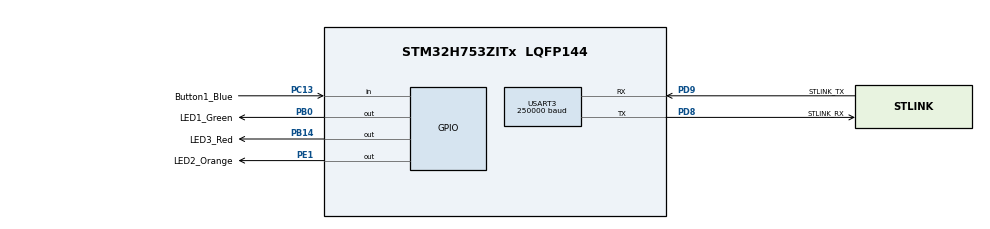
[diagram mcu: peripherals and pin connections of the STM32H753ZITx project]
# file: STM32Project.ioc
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CORTEX_M7.CPU_DCache=Disabled
CORTEX_M7.CPU_ICache=Disabled
CORTEX_M7.MPU_Control=__NULL
CORTEX_M7.default_mode_Activation=1
Mcu.Family=STM32H7
Mcu.Name=STM32H753ZITx
Mcu.Package=LQFP144
NVIC.PriorityGroup=NVIC_PRIORITYGROUP_4
NVIC.TIM7_IRQn=true\:15\:0\:false\:false\:true\:false\:true\:true
NVIC.TimeBase=TIM7_IRQn
NVIC.TimeBaseIP=TIM7
PA13\ (JTMS/SWDIO).Mode=Trace_Asynchronous_SW
PA13\ (JTMS/SWDIO).Signal=DEBUG_JTMS-SWDIO
PA14\ (JTCK/SWCLK).Mode=Trace_Asynchronous_SW
PA14\ (JTCK/SWCLK).Signal=DEBUG_JTCK-SWCLK
PB0.GPIO_Label=LED1_Green
PB0.Signal=GPIO_Output
PB14.GPIO_Label=LED3_Red
PB14.Signal=GPIO_Output
PB3\ (JTDO/TRACESWO).Mode=Trace_Asynchronous_SW
PB3\ (JTDO/TRACESWO).Signal=DEBUG_JTDO-SWO
PC13.GPIO_Label=Button1_Blue
PC13.Signal=GPIO_Input
PC14-OSC32_IN\ (OSC32_IN).Mode=LSE-External-Oscillator
PC14-OSC32_IN\ (OSC32_IN).Signal=RCC_OSC32_IN
PC15-OSC32_OUT\ (OSC32_OUT).Mode=LSE-External-Oscillator
PC15-OSC32_OUT\ (OSC32_OUT).Signal=RCC_OSC32_OUT
PD8.GPIO_Label=STLINK_RX
PD8.GPIO_Speed=GPIO_SPEED_FREQ_VERY_HIGH
PD8.Mode=Asynchronous
PD8.Signal=USART3_TX
PD9.GPIO_Label=STLINK_TX
PD9.GPIO_Speed=GPIO_SPEED_FREQ_VERY_HIGH
PD9.Mode=Asynchronous
PD9.Signal=USART3_RX
PE1.GPIO_Label=LED2_Orange
PE1.Signal=GPIO_Output
PH0-OSC_IN\ (PH0).Mode=HSE-External-Clock-Source
PH0-OSC_IN\ (PH0).Signal=RCC_OSC_IN
PH1-OSC_OUT\ (PH1).Signal=RCC_OSC_OUT
ProjectManager.HeapSize=0x400
ProjectManager.StackSize=0x1000
ProjectManager.TargetToolchain=CMake
RCC.ADCFreq_Value=50000000
RCC.APB1Freq_Value=120000000
RCC.APB2Freq_Value=120000000
RCC.APB3Freq_Value=120000000
RCC.APB4Freq_Value=120000000
RCC.CortexFreq_Value=480000000
RCC.D1PPRE=RCC_APB3_DIV2
RCC.D2PPRE1=RCC_APB1_DIV2
RCC.D2PPRE2=RCC_APB2_DIV2
RCC.D3PPRE=RCC_APB4_DIV2
RCC.DIVM1=1
RCC.DIVM2=1
RCC.DIVM3=1
RCC.DIVN1=192
RCC.DIVN2=20
RCC.DIVN3=184
RCC.DIVQ1=4
RCC.HCLKFreq_Value=240000000
RCC.HPRE=RCC_HCLK_DIV2
RCC.HSE_VALUE=5000000
RCC.PLLFRACN=0
RCC.PLLSourceVirtual=RCC_PLLSOURCE_HSE
RCC.PWR_Regulator_Voltage_Scale=PWR_REGULATOR_VOLTAGE_SCALE0
RCC.RTCClockSelection=RCC_RTCCLKSOURCE_LSE
RCC.SYSCLKFreq_VALUE=480000000
RCC.SYSCLKSource=RCC_SYSCLKSOURCE_PLLCLK
RCC.USBFreq_Value=240000000
RTC.WeekDay=RTC_WEEKDAY_THURSDAY
RTC.Year=26
USART3.BaudRate=250000
USART3.VirtualMode-Asynchronous=VM_ASYNC
VP_MEMORYMAP_VS_MEMORYMAP.Mode=CurAppReg
VP_RTC_VS_RTC_Activate.Mode=RTC_Enabled
VP_RTC_VS_RTC_Calendar.Mode=RTC_Calendar
VP_SYS_VS_tim7.Mode=TIM7
board=NUCLEO-H753ZI

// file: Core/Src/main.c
/* USER CODE BEGIN Header */
/**
  ******************************************************************************
  * @file           : main.c
  * @brief          : Main program body
  ******************************************************************************
  * @attention
  *
  * Copyright (c) 2026 STMicroelectronics.
  * All rights reserved.
  *
  * This software is licensed under terms that can be found in the LICENSE file
  * in the root directory of this software component.
  * If no LICENSE file comes with this software, it is provided AS-IS.
  *
  ******************************************************************************
  */
/* USER CODE END Header */
#include "main.h"
#include "rtc.h"
#include "usart.h"
#include "gpio.h"

void SystemClock_Config(void);
/* USER CODE BEGIN PFP */
extern void Setup(void);
extern void Loop(void);
/* USER CODE END PFP */

int main(void)
{

  /* MCU Configuration--------------------------------------------------------*/

  /* Reset of all peripherals, Initializes the Flash interface and the Systick. */
  HAL_Init();

  /* Configure the system clock */
  SystemClock_Config();

  /* Initialize all configured peripherals */
  MX_GPIO_Init();
  MX_USART3_UART_Init();
  MX_RTC_Init();

  /* Infinite loop */
  /* USER CODE BEGIN WHILE */
  Setup(); // Call the C++ application main function in ./Application/application.cpp.

  while (1)
  {
    Loop(); // Cyclic call the C++ application loop function in ./Application/application.cpp.
    /* USER CODE END WHILE */

  }
}

void SystemClock_Config(void)
{
  RCC_OscInitTypeDef RCC_OscInitStruct = {0};
  RCC_ClkInitTypeDef RCC_ClkInitStruct = {0};

  /** Supply configuration update enable
  */
  HAL_PWREx_ConfigSupply(PWR_LDO_SUPPLY);

  /** Configure the main internal regulator output voltage
  */
  __HAL_PWR_VOLTAGESCALING_CONFIG(PWR_REGULATOR_VOLTAGE_SCALE0);

  while(!__HAL_PWR_GET_FLAG(PWR_FLAG_VOSRDY)) {}

  /** Configure LSE Drive Capability
  */
  HAL_PWR_EnableBkUpAccess();
  __HAL_RCC_LSEDRIVE_CONFIG(RCC_LSEDRIVE_LOW);

  /** Initializes the RCC Oscillators according to the specified parameters
  * in the RCC_OscInitTypeDef structure.
  */
  RCC_OscInitStruct.OscillatorType = RCC_OSCILLATORTYPE_HSE|RCC_OSCILLATORTYPE_LSE;
  RCC_OscInitStruct.HSEState = RCC_HSE_BYPASS;
  RCC_OscInitStruct.LSEState = RCC_LSE_ON;
  RCC_OscInitStruct.PLL.PLLState = RCC_PLL_ON;
  RCC_OscInitStruct.PLL.PLLSource = RCC_PLLSOURCE_HSE;
  RCC_OscInitStruct.PLL.PLLM = 1;
  RCC_OscInitStruct.PLL.PLLN = 192;
  RCC_OscInitStruct.PLL.PLLP = 2;
  RCC_OscInitStruct.PLL.PLLQ = 4;
  RCC_OscInitStruct.PLL.PLLR = 2;
  RCC_OscInitStruct.PLL.PLLRGE = RCC_PLL1VCIRANGE_2;
  RCC_OscInitStruct.PLL.PLLVCOSEL = RCC_PLL1VCOWIDE;
  RCC_OscInitStruct.PLL.PLLFRACN = 0;
  if (HAL_RCC_OscConfig(&RCC_OscInitStruct) != HAL_OK)
  {
    Error_Handler();
  }

  /** Initializes the CPU, AHB and APB buses clocks
  */
  RCC_ClkInitStruct.ClockType = RCC_CLOCKTYPE_HCLK|RCC_CLOCKTYPE_SYSCLK
                              |RCC_CLOCKTYPE_PCLK1|RCC_CLOCKTYPE_PCLK2
                              |RCC_CLOCKTYPE_D3PCLK1|RCC_CLOCKTYPE_D1PCLK1;
  RCC_ClkInitStruct.SYSCLKSource = RCC_SYSCLKSOURCE_PLLCLK;
  RCC_ClkInitStruct.SYSCLKDivider = RCC_SYSCLK_DIV1;
  RCC_ClkInitStruct.AHBCLKDivider = RCC_HCLK_DIV2;
  RCC_ClkInitStruct.APB3CLKDivider = RCC_APB3_DIV2;
  RCC_ClkInitStruct.APB1CLKDivider = RCC_APB1_DIV2;
  RCC_ClkInitStruct.APB2CLKDivider = RCC_APB2_DIV2;
  RCC_ClkInitStruct.APB4CLKDivider = RCC_APB4_DIV2;

  if (HAL_RCC_ClockConfig(&RCC_ClkInitStruct, FLASH_LATENCY_4) != HAL_OK)
  {
    Error_Handler();
  }
}

void HAL_TIM_PeriodElapsedCallback(TIM_HandleTypeDef *htim)
{
  if (htim->Instance == TIM7)
  {
    HAL_IncTick();
  }
}

void Error_Handler(void)
{
  __disable_irq();
  while (1)
  {
  }
}
